# RS1xxxx register map
Vendor: Silicon Lab Inc.; Series: ARMCM4; File version: 1.2
CPU: CM4 r1p0, little endian, MPU, FPU, 6 interrupt priority bits
Registers are 32-bit, read-write, reset 0x0 unless marked. A register's access mark holds for its fields unless they carry their own. Offsets are from the block's base; [hi:lo] are bit positions; 'fields as' and 'values as' point back to an identical list.

## CRC_Accelerator — CRC is used in all wireless communication as a first data integrity check
Base 0x45080000
0x00 CRC_GEN_CTRL_SET_REG — General control set register
  [0] SOFT_RST — Soft reset. This clears the FIFO and settles all the state machines to their IDLE
    1=Enable (Soft reset will be triggered.); 0=Disable (No effect)
0x04 CRC_GEN_CTRL_RESET — General control reset register
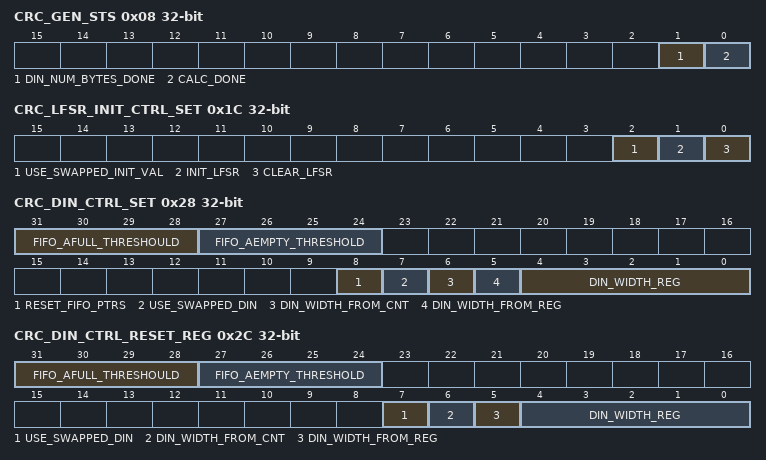
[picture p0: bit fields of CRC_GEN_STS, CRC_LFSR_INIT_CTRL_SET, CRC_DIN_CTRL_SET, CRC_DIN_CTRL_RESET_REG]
0x08 CRC_GEN_STS ro — General status register
  [1] DIN_NUM_BYTES_DONE — When number of bytes requested for computation of final CRC is read from fifo by internal FSM, this will get set to 1 otherwise 0.
  [0] CALC_DONE — When the computation of final CRC with the data out of fifo, this will get set to 1 otherwise 0
0x0C CRC_POLYNOMIAL (reset mask 0xFFFF) — This register holds the polynomial with which the final CRC is computed.
  [31:0] POLYNOMIAL — Polynomial register. This register holds the polynomial with which the final CRC is computed.When write Polynomial will be updated.When read read polynomial.
0x10 CRC_POLYNOMIAL_CTRL_SET — Polynomial control set register
  [4:0] POLYNOMIAL_WIDTH_SET — Polynomial width set. Number of bits/width of the polynomial has to be written here for the computation of final CRC. If a new width has to be configured, clear the existing length first by writing 0x1f in polynomial_ctrl_reset register. When read, actual polynomial width is read.
0x14 CRC_POLYNOMIAL_CTRL_RESET — Polynomial control set register
  [4:0] POLYNOMIAL_WIDTH_SET — Polynomial width reset. If a new width has to be configured, clear the existing length first by writing 0x1f. When read, actual polynomial width is read.
0x18 CRC_LFSR_INIT_VAL (reset mask 0xFFFF) — LFSR initial value
  [31:0] LFSR_INIT — This holds LFSR initialization value. When ever LFSR needs to be initialized, this has to be updated with the init value and trigger init_lfsr in LFSR_INIT_CTRL_SET register. For example, in WiFi case, 0xffffffff is used as init value of LFSR.
0x1C CRC_LFSR_INIT_CTRL_SET — LFSR state initialization control set register
  [2] USE_SWAPPED_INIT_VAL — Use bit swapped init value. If this is set bit swapped version of LFSR init value will be loaded / initialized to LFSR state
    1=Enable (write 1 use_swapped_init_val will be enabled read 1 use_swapped_init_val is enabled); 0=Disable (write 0 No effect read 0 use_swapped_init_val is disabled.)
  [1] INIT_LFSR — Initialize LFSR state. When this is set LFSR state will be initialized with LFSR_INIT_VAL/bit swapped LFSR_INIT_VAL in the next cycle
    1=Enable (Initialization will be done in next cycle); 0=Disable (No effect)
  [0] CLEAR_LFSR — Clear LFSR state. When this is set, LFSR state is cleared to 0
    1=Enable (LFSR state will be cleared in next cycle); 0=Disable (No effect)
0x20 CRC_LFSR_INIT_CTRL_RESET — LFSR state initialization control reset register
  [2] USE_SWAPPED_INIT_VAL — Use bit swapped init value. If this is set bit swapped version of LFSR init value will be loaded / initialized to LFSR state
    values as CRC_LFSR_INIT_CTRL_SET.USE_SWAPPED_INIT_VAL
0x24 CRC_DIN_FIFO wo (reset mask 0xFFFF) — Data input FIFO register
  [31:0] DIN_FIFO — FIFO input port is mapped to this register. Data on which the final CRC has to be computed has to be loaded to this FIFO
0x28 CRC_DIN_CTRL_SET (reset mask 0xFFFF) — Input data control set register
  [31:28] FIFO_AFULL_THRESHOULD — FIFO almost full threshold value. This has to be cleared by writing 0xf0000000 into din_ctrl_reset before updating any new value
  [27:24] FIFO_AEMPTY_THRESHOLD — FIFO almost empty threshold value. This has to be cleared by writing 0x0f000000 into din_ctrl_reset before updating any new value.
  [8] RESET_FIFO_PTRS — Reset fifo pointer. This clears the FIFO.When this is set, FIFO will be cleared.
    1=Enable (write 1 FIFO will be cleared in the next cycle.); 0=Disable (write 0 No effect)
  [7] USE_SWAPPED_DIN — Use bit swapped input data. If this is set, input data will be swapped and filled in to FIFO. Whatever read out from FIFO will be directly fed to LFSR engine.
    1=Enable (write 1 Bit swapped data will be filled in to FIFO read 1 Bit swapped data is filled in to FIFO); 0=Disable (write 0 No effect read 0 Direct write data is filled in to FIFO.)
  [6] DIN_WIDTH_FROM_CNT — Valid number of bits in the input data. In default, number of valid bits in the input data is taken from ULI (uli_be). If this is set, a mix of ULI length and number of bytes remaining will form the valid bits (which ever is less that will be considered as valid bits).
    1=Enable (write 1 Din width will be taken from both apb and cnt value. read 1 Din width is from ULI and cnt value.); 0=Disable (write 0 No effect read 0 Din width does not consider cnt value.This overrides the din_width_from_reg)
  [5] DIN_WIDTH_FROM_REG — Valid number of bits in the input data. In default, number of valid bits in the input data is taken from ULI (uli_be). If this is set, whatever is the input size, only din_ctrl_reg[4:0] is taken as valid length/width for inout data.
    1=Enable (write 1 Din valid width will be taken from reg. read 1 Din valid width is taken from reg.); 0=Disable (write 0 No effect read 0 Din valid width is not taken from reg)
  [4:0] DIN_WIDTH_REG — Valid number of bits in the input data in din_width_from_reg set mode. Before writing a new value into this, din_ctrl_reset_reg has to be written with 0x1f to clear this field as these are set/clear bits.
0x2C CRC_DIN_CTRL_RESET_REG (reset mask 0xFFFF) — Input data control set register
  [31:28] FIFO_AFULL_THRESHOULD — FIFO almost full threshold value. This has to be cleared by writing 0xf0000000 into din_ctrl_reset before updating any new value
  [27:24] FIFO_AEMPTY_THRESHOLD — FIFO almost empty threshold value. This has to be cleared by writing 0x0f000000 into din_ctrl_reset before updating any new value.
  [7] USE_SWAPPED_DIN — Use bit swapped input data. If this is set input data will be swapped and filled in to FIFO. Whatever read out from FIFO will be directly fed to LFSR engine.
    values as CRC_DIN_CTRL_SET.USE_SWAPPED_DIN
  [6] DIN_WIDTH_FROM_CNT — Valid number of bits in the input data. In default, number of valid bits in the input data is taken from ULI (uli_be). If this is set, a mix of ULI length and number of bytes remaining will form the valid bits (which ever is less that will be considered as valid bits).
    values as CRC_DIN_CTRL_SET.DIN_WIDTH_FROM_CNT
  [5] DIN_WIDTH_FROM_REG — Valid number of bits in the input data. In default, number of valid bits in the input data is taken from ULI (uli_be). If this is set, whatever is the input size, only din_ctrl_reg[4:0] is taken as valid length/width for inout data.
    values as CRC_DIN_CTRL_SET.DIN_WIDTH_FROM_REG
  [4:0] DIN_WIDTH_REG — Valid number of bits in the input data in din_width_from_reg set mode. Before writing a new value into this, din_ctrl_reset_reg has to be written with 0x1f to clear this field as these are set/clear bits.
0x30 CRC_DIN_NUM_BYTES (reset mask 0xFFFF) — Data input FIFO register
  [31:0] DIN_NUM_BYTES — in out data number of bytes
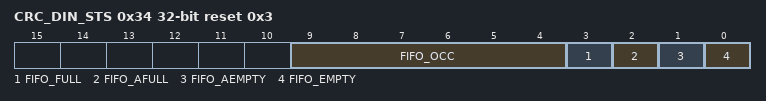
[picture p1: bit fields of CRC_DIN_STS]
0x34 CRC_DIN_STS ro reset 0x3 — Input data status register
  [9:4] FIFO_OCC — FIFO occupancy
  [3] FIFO_FULL — FIFO full indication status
  [2] FIFO_AFULL — FIFO almost full indication status
  [1] FIFO_AEMPTY — FIFO almost empty indication status.
  [0] FIFO_EMPTY — FIFO empty indication status
0x38 CRC_LFSR_STATE reset 0x3 — LFSR state register
  [31:0] LFSR_STATE — If LFSR dynamic loading is required this can be used for writing the LFSR state directly.
